VERSION ""

NS_ :

BS_:

BU_: VCU ACU

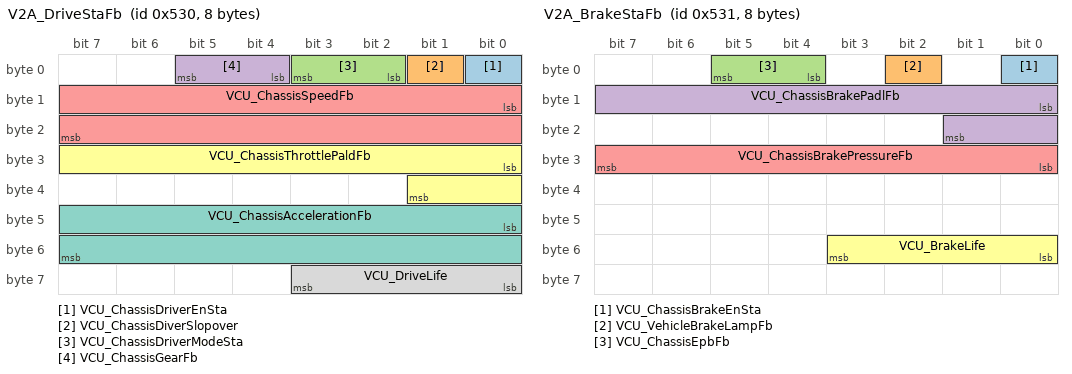
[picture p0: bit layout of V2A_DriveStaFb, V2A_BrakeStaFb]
BO_ 1328 V2A_DriveStaFb: 8 VCU
 SG_ VCU_ChassisDriverEnSta : 0|1@1+ (1,0) [0|1] ""   ACU
 SG_ VCU_ChassisDiverSlopover : 1|1@1+ (1,0) [0|1] ""   ACU
 SG_ VCU_ChassisDriverModeSta : 2|2@1+ (1,0) [0|3] ""   ACU
 SG_ VCU_ChassisGearFb : 4|2@1+ (1,0) [0|3] ""   ACU
 SG_ VCU_ChassisSpeedFb : 8|16@1- (0.01,0) [-50|50] "m/s"   ACU
 SG_ VCU_ChassisThrottlePaldFb : 24|10@1+ (0.1,0) [0|100] "%"   ACU
 SG_ VCU_ChassisAccelerationFb : 40|16@1- (0.01,0) [-20|20] "m/s2"   ACU
 SG_ VCU_DriveLife : 56|4@1+ (1,0) [0|15] ""   ACU

BO_ 1329 V2A_BrakeStaFb: 8 VCU
 SG_ VCU_ChassisBrakeEnSta : 0|1@1+ (1,0) [0|1] ""   ACU
 SG_ VCU_VehicleBrakeLampFb : 2|1@1+ (1,0) [0|1] ""   ACU
 SG_ VCU_ChassisEpbFb : 4|2@1+ (1,0) [0|3] ""   ACU
 SG_ VCU_ChassisBrakePadlFb : 8|10@1+ (0.1,0) [0|100] "%"   ACU
 SG_ VCU_ChassisBrakePressureFb : 24|8@1+ (1,0) [0|100] "bar"   ACU
 SG_ VCU_BrakeLife : 48|4@1+ (1,0) [0|15] ""   ACU

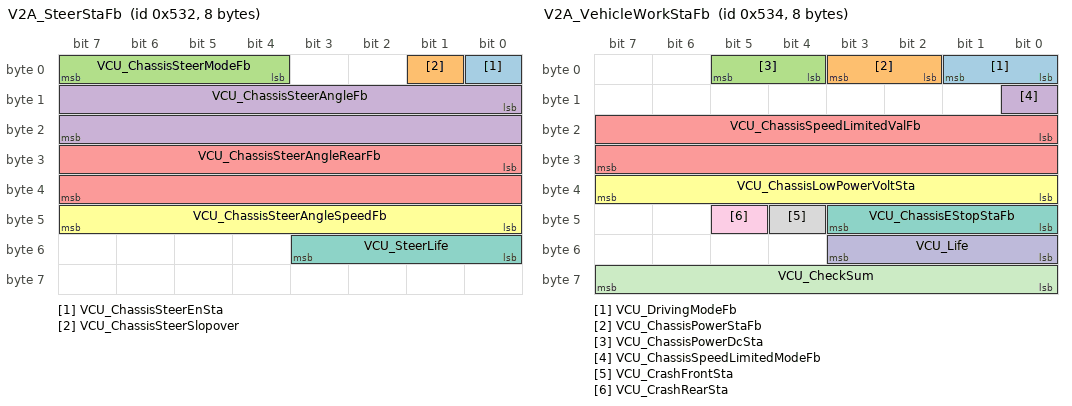
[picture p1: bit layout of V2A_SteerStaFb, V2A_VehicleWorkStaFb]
BO_ 1330 V2A_SteerStaFb: 8 VCU
 SG_ VCU_ChassisSteerEnSta : 0|1@1+ (1,0) [0|1] ""   ACU
 SG_ VCU_ChassisSteerSlopover : 1|1@1+ (1,0) [0|1] ""   ACU
 SG_ VCU_ChassisSteerModeFb : 4|4@1+ (1,0) [0|4] ""   ACU
 SG_ VCU_ChassisSteerAngleFb : 8|16@1- (1,0) [-500|500] "deg"   ACU
 SG_ VCU_ChassisSteerAngleRearFb : 24|16@1- (1,0) [-500|500] "deg"   ACU
 SG_ VCU_ChassisSteerAngleSpeedFb : 40|8@1+ (2,0) [0|500] "deg/s"   ACU
 SG_ VCU_SteerLife : 48|4@1+ (1,0) [0|15] ""   ACU

BO_ 1332 V2A_VehicleWorkStaFb: 8 VCU
 SG_ VCU_DrivingModeFb : 0|2@1+ (1,0) [0|3] ""   ACU
 SG_ VCU_ChassisPowerStaFb : 2|2@1+ (1,0) [0|3] ""   ACU
 SG_ VCU_ChassisPowerDcSta : 4|2@1+ (1,0) [0|2] ""   ACU
 SG_ VCU_ChassisSpeedLimitedModeFb : 8|1@1+ (1,0) [0|1] ""   ACU
 SG_ VCU_ChassisSpeedLimitedValFb : 16|16@1+ (0.1,0) [0|50] "m/s"   ACU
 SG_ VCU_ChassisLowPowerVoltSta : 32|8@1+ (0.1,0) [0|25] "V"   ACU
 SG_ VCU_ChassisEStopStaFb : 40|4@1+ (1,0) [0|3] ""   ACU
 SG_ VCU_CrashFrontSta : 44|1@1+ (1,0) [0|1] ""   ACU
 SG_ VCU_CrashRearSta : 45|1@1+ (1,0) [0|1] ""   ACU
 SG_ VCU_Life : 48|4@1+ (1,0) [0|15] ""   ACU
 SG_ VCU_CheckSum : 56|8@1+ (1,0) [0|255] ""   ACU

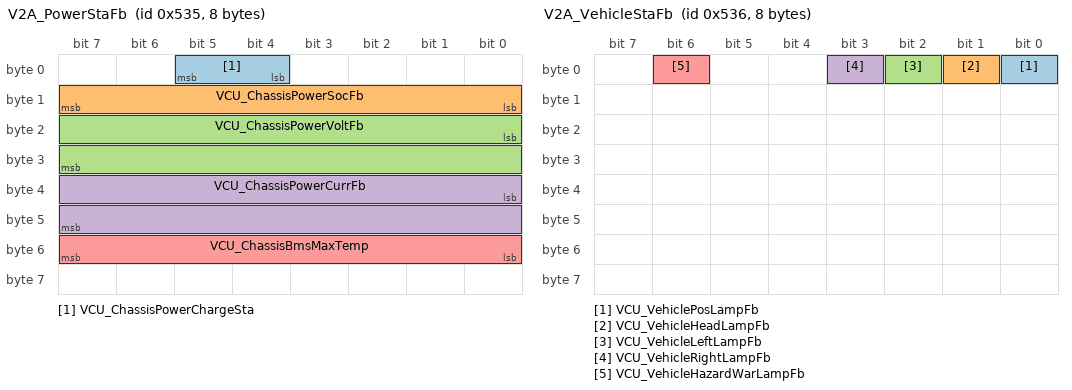
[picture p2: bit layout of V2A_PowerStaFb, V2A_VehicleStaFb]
BO_ 1333 V2A_PowerStaFb: 8 VCU
 SG_ VCU_ChassisPowerChargeSta : 4|2@1+ (1,0) [0|2] ""   ACU
 SG_ VCU_ChassisPowerSocFb : 8|8@1+ (1,0) [0|100] "%"   ACU
 SG_ VCU_ChassisPowerVoltFb : 16|16@1+ (0.1,0) [0|1000] "V"   ACU
 SG_ VCU_ChassisPowerCurrFb : 32|16@1+ (0.1,-1000) [-1000|1000] "A"   ACU
 SG_ VCU_ChassisBmsMaxTemp : 48|8@1+ (1,-40) [-40|80] "℃"   ACU

BO_ 1334 V2A_VehicleStaFb: 8 VCU
 SG_ VCU_VehiclePosLampFb : 0|1@1+ (1,0) [0|1] ""   ACU
 SG_ VCU_VehicleHeadLampFb : 1|1@1+ (1,0) [0|1] ""   ACU
 SG_ VCU_VehicleLeftLampFb : 2|1@1+ (1,0) [0|1] ""   ACU
 SG_ VCU_VehicleRightLampFb : 3|1@1+ (1,0) [0|1] ""   ACU
 SG_ VCU_VehicleHazardWarLampFb : 6|1@1+ (1,0) [0|1] ""   ACU

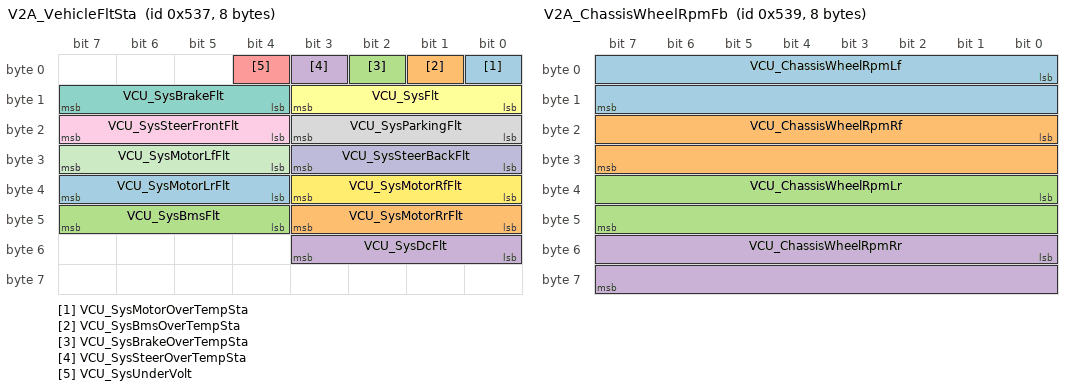
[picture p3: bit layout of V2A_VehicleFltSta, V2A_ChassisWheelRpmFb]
BO_ 1335 V2A_VehicleFltSta: 8 VCU
 SG_ VCU_SysMotorOverTempSta : 0|1@1+ (1,0) [0|1] ""   ACU
 SG_ VCU_SysBmsOverTempSta : 1|1@1+ (1,0) [0|1] ""   ACU
 SG_ VCU_SysBrakeOverTempSta : 2|1@1+ (1,0) [0|1] ""   ACU
 SG_ VCU_SysSteerOverTempSta : 3|1@1+ (1,0) [0|1] ""   ACU
 SG_ VCU_SysUnderVolt : 4|1@1+ (1,0) [0|1] ""   ACU
 SG_ VCU_SysFlt : 8|4@1+ (1,0) [0|4] ""   ACU
 SG_ VCU_SysBrakeFlt : 12|4@1+ (1,0) [0|4] ""   ACU
 SG_ VCU_SysParkingFlt : 16|4@1+ (1,0) [0|4] ""   ACU
 SG_ VCU_SysSteerFrontFlt : 20|4@1+ (1,0) [0|4] ""   ACU
 SG_ VCU_SysSteerBackFlt : 24|4@1+ (1,0) [0|4] ""   ACU
 SG_ VCU_SysMotorLfFlt : 28|4@1+ (1,0) [0|4] ""   ACU
 SG_ VCU_SysMotorRfFlt : 32|4@1+ (1,0) [0|4] ""   ACU
 SG_ VCU_SysMotorLrFlt : 36|4@1+ (1,0) [0|4] ""   ACU
 SG_ VCU_SysMotorRrFlt : 40|4@1+ (1,0) [0|4] ""   ACU
 SG_ VCU_SysBmsFlt : 44|4@1+ (1,0) [0|4] ""   ACU
 SG_ VCU_SysDcFlt : 48|4@1+ (1,0) [0|4] ""   ACU

BO_ 1337 V2A_ChassisWheelRpmFb: 8 VCU
 SG_ VCU_ChassisWheelRpmLf : 0|16@1- (1,0) [-2000|2000] "rpm"   ACU
 SG_ VCU_ChassisWheelRpmRf : 16|16@1- (1,0) [-2000|2000] "rpm"   ACU
 SG_ VCU_ChassisWheelRpmLr : 32|16@1- (1,0) [-2000|2000] "rpm"   ACU
 SG_ VCU_ChassisWheelRpmRr : 48|16@1- (1,0) [-2000|2000] "rpm"   ACU

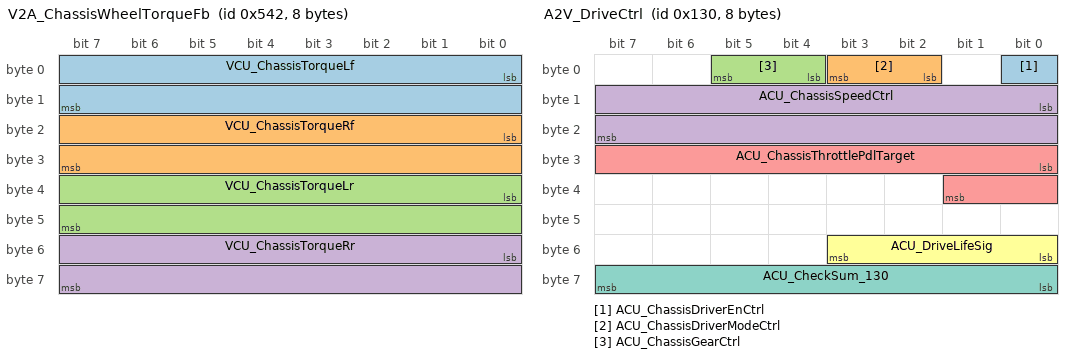
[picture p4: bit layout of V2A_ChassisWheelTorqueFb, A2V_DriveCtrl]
BO_ 1346 V2A_ChassisWheelTorqueFb: 8 VCU
 SG_ VCU_ChassisTorqueLf : 0|16@1- (0.1,0) [-200|200] "Nm"   ACU
 SG_ VCU_ChassisTorqueRf : 16|16@1- (0.1,0) [-200|200] "Nm"   ACU
 SG_ VCU_ChassisTorqueLr : 32|16@1- (0.1,0) [-200|200] "Nm"   ACU
 SG_ VCU_ChassisTorqueRr : 48|16@1- (0.1,0) [-200|200] "Nm"   ACU

BO_ 304 A2V_DriveCtrl: 8 ACU
 SG_ ACU_ChassisDriverEnCtrl : 0|1@1+ (1,0) [0|1] ""   VCU
 SG_ ACU_ChassisDriverModeCtrl : 2|2@1+ (1,0) [0|3] ""   VCU
 SG_ ACU_ChassisGearCtrl : 4|2@1+ (1,0) [0|3] ""   VCU
 SG_ ACU_ChassisSpeedCtrl : 8|16@1+ (0.01,0) [0|50] "m/s"   VCU
 SG_ ACU_ChassisThrottlePdlTarget : 24|10@1+ (0.1,0) [0|100] "%"   VCU
 SG_ ACU_DriveLifeSig : 48|4@1+ (1,0) [0|15] ""   VCU
 SG_ ACU_CheckSum_130 : 56|8@1+ (1,0) [0|255] ""   VCU

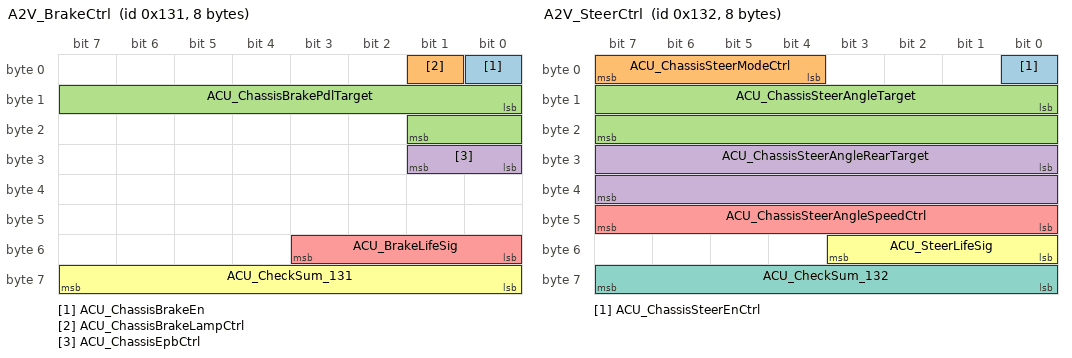
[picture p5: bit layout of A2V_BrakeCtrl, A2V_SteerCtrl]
BO_ 305 A2V_BrakeCtrl: 8 ACU
 SG_ ACU_ChassisBrakeEn : 0|1@1+ (1,0) [0|1] ""   VCU
 SG_ ACU_ChassisBrakeLampCtrl : 1|1@1+ (1,0) [0|1] ""   VCU
 SG_ ACU_ChassisBrakePdlTarget : 8|10@1+ (0.1,0) [0|100] "%"   VCU
 SG_ ACU_ChassisEpbCtrl : 24|2@1+ (1,0) [0|2] ""   VCU
 SG_ ACU_BrakeLifeSig : 48|4@1+ (1,0) [0|15] ""   VCU
 SG_ ACU_CheckSum_131 : 56|8@1+ (1,0) [0|255] ""   VCU

BO_ 306 A2V_SteerCtrl: 8 ACU
 SG_ ACU_ChassisSteerEnCtrl : 0|1@1+ (1,0) [0|1] ""   VCU
 SG_ ACU_ChassisSteerModeCtrl : 4|4@1+ (1,0) [0|4] ""   VCU
 SG_ ACU_ChassisSteerAngleTarget : 8|16@1- (1,0) [-500|500] "deg"   VCU
 SG_ ACU_ChassisSteerAngleRearTarget : 24|16@1- (1,0) [-500|500] "deg"   VCU
 SG_ ACU_ChassisSteerAngleSpeedCtrl : 40|8@1+ (2,0) [0|500] "deg/s"   VCU
 SG_ ACU_SteerLifeSig : 48|4@1+ (1,0) [0|15] ""   VCU
 SG_ ACU_CheckSum_132 : 56|8@1+ (1,0) [0|255] ""   VCU

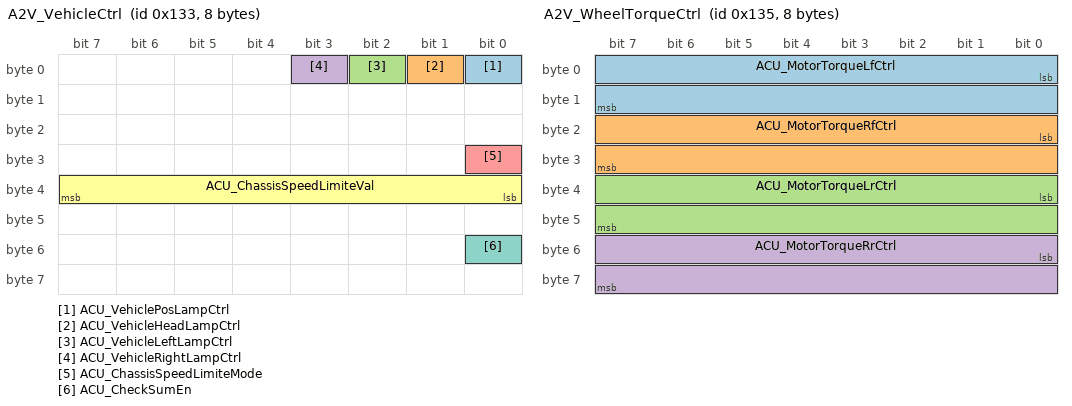
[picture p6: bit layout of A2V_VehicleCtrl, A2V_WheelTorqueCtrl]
BO_ 307 A2V_VehicleCtrl: 8 ACU
 SG_ ACU_VehiclePosLampCtrl : 0|1@1+ (1,0) [0|1] ""   VCU
 SG_ ACU_VehicleHeadLampCtrl : 1|1@1+ (1,0) [0|1] ""   VCU
 SG_ ACU_VehicleLeftLampCtrl : 2|1@1+ (1,0) [0|1] ""   VCU
 SG_ ACU_VehicleRightLampCtrl : 3|1@1+ (1,0) [0|1] ""   VCU
 SG_ ACU_ChassisSpeedLimiteMode : 24|1@1+ (1,0) [0|1] ""   VCU
 SG_ ACU_ChassisSpeedLimiteVal : 32|8@1+ (0.1,0) [1|20] "m/s"   VCU
 SG_ ACU_CheckSumEn : 48|1@1+ (1,0) [0|1] ""   VCU

BO_ 309 A2V_WheelTorqueCtrl: 8 ACU
 SG_ ACU_MotorTorqueLfCtrl : 0|16@1- (0.1,0) [-200|200] "Nm"   VCU
 SG_ ACU_MotorTorqueRfCtrl : 16|16@1- (0.1,0) [-200|200] "Nm"   VCU
 SG_ ACU_MotorTorqueLrCtrl : 32|16@1- (0.1,0) [-200|200] "Nm"   VCU
 SG_ ACU_MotorTorqueRrCtrl : 48|16@1- (0.1,0) [-200|200] "Nm"   VCU

CM_ BO_ 1328 "车辆驱动状态反馈";
CM_ SG_ 1328 VCU_ChassisDriverEnSta "驱动使能状态";
CM_ SG_ 1328 VCU_ChassisDiverSlopover "驱动控制越界提醒";
CM_ SG_ 1328 VCU_ChassisDriverModeSta "驱动模式反馈";
CM_ SG_ 1328 VCU_ChassisGearFb "档位状态";
CM_ SG_ 1328 VCU_ChassisSpeedFb "车速实际反馈";
CM_ SG_ 1328 VCU_ChassisThrottlePaldFb "油门请求值反馈";
CM_ SG_ 1328 VCU_ChassisAccelerationFb "车辆加速度";
CM_ SG_ 1328 VCU_DriveLife "VCU循环计数";
CM_ BO_ 1329 "车辆制动状态反馈";
CM_ SG_ 1329 VCU_ChassisBrakeEnSta "制动使能状态";
CM_ SG_ 1329 VCU_VehicleBrakeLampFb "制动灯状态反馈";
CM_ SG_ 1329 VCU_ChassisEpbFb "驻车状态";
CM_ SG_ 1329 VCU_ChassisBrakePadlFb "制动踏板值反馈";
CM_ SG_ 1329 VCU_ChassisBrakePressureFb "制动压力反馈";
CM_ SG_ 1329 VCU_BrakeLife "VCU循环计数";
CM_ BO_ 1330 "车辆转向状态反馈";
CM_ SG_ 1330 VCU_ChassisSteerEnSta "转向使能状态";
CM_ SG_ 1330 VCU_ChassisSteerSlopover "转向控制越界提醒";
CM_ SG_ 1330 VCU_ChassisSteerModeFb "转向模式反馈";
CM_ SG_ 1330 VCU_ChassisSteerAngleFb "前转向方向盘转角反馈";
CM_ SG_ 1330 VCU_ChassisSteerAngleRearFb "后转向方向盘转角反馈";
CM_ SG_ 1330 VCU_ChassisSteerAngleSpeedFb "设置的转向转角速度反馈";
CM_ SG_ 1330 VCU_SteerLife "VCU循环计数";
CM_ BO_ 1332 "车辆工作状态反馈";
CM_ SG_ 1332 VCU_DrivingModeFb "驾驶模式反馈";
CM_ SG_ 1332 VCU_ChassisPowerStaFb "车辆上电状态反馈";
CM_ SG_ 1332 VCU_ChassisPowerDcSta "DC工作状态";
CM_ SG_ 1332 VCU_ChassisSpeedLimitedModeFb "车辆限速状态";
CM_ SG_ 1332 VCU_ChassisSpeedLimitedValFb "车辆限速值反馈";
CM_ SG_ 1332 VCU_ChassisLowPowerVoltSta "低压蓄电池电压";
CM_ SG_ 1332 VCU_ChassisEStopStaFb "紧急停车状态反馈";
CM_ SG_ 1332 VCU_CrashFrontSta "车辆前碰撞传感器反馈";
CM_ SG_ 1332 VCU_CrashRearSta "车辆后碰撞传感器反馈";
CM_ SG_ 1332 VCU_Life "VCU循环计数";
CM_ SG_ 1332 VCU_CheckSum "校验sum=byte0 xor byte1 xor...byte6";
CM_ BO_ 1333 "车辆动力电源状态反馈";
CM_ SG_ 1333 VCU_ChassisPowerChargeSta "车辆充电状态";
CM_ SG_ 1333 VCU_ChassisPowerSocFb "车辆动力电池电量";
CM_ SG_ 1333 VCU_ChassisPowerVoltFb "车辆动力电池电压";
CM_ SG_ 1333 VCU_ChassisPowerCurrFb "车辆动力电池电流";
CM_ SG_ 1333 VCU_ChassisBmsMaxTemp "BMS最高单体温度";
CM_ BO_ 1334 "车辆车身及灯光反馈";
CM_ SG_ 1334 VCU_VehiclePosLampFb "位置灯状态反馈";
CM_ SG_ 1334 VCU_VehicleHeadLampFb "近光灯状态反馈";
CM_ SG_ 1334 VCU_VehicleLeftLampFb "左转向灯状态反馈";
CM_ SG_ 1334 VCU_VehicleRightLampFb "右转向灯状态反馈";
CM_ SG_ 1334 VCU_VehicleHazardWarLampFb "危险警示灯开关状态";
CM_ BO_ 1335 "车辆警告和故障";
CM_ SG_ 1335 VCU_SysMotorOverTempSta "电机系统过温";
CM_ SG_ 1335 VCU_SysBmsOverTempSta "电池系统过温";
CM_ SG_ 1335 VCU_SysBrakeOverTempSta "制动系统过温";
CM_ SG_ 1335 VCU_SysSteerOverTempSta "转向系统过温";
CM_ SG_ 1335 VCU_SysUnderVolt "蓄电池电压过低";
CM_ SG_ 1335 VCU_SysFlt "系统故障";
CM_ SG_ 1335 VCU_SysBrakeFlt "制动系统故障";
CM_ SG_ 1335 VCU_SysParkingFlt "驻车系统故障";
CM_ SG_ 1335 VCU_SysSteerFrontFlt "前转向系统故障";
CM_ SG_ 1335 VCU_SysSteerBackFlt "后转向系统故障";
CM_ SG_ 1335 VCU_SysMotorLfFlt "左前电机系统故障";
CM_ SG_ 1335 VCU_SysMotorRfFlt "右前电机系统故障";
CM_ SG_ 1335 VCU_SysMotorLrFlt "左后电机系统故障";
CM_ SG_ 1335 VCU_SysMotorRrFlt "右后电机系统故障";
CM_ SG_ 1335 VCU_SysBmsFlt "BMS系统故障";
CM_ SG_ 1335 VCU_SysDcFlt "DC系统故障";
CM_ BO_ 1337 "车轮转速反馈";
CM_ SG_ 1337 VCU_ChassisWheelRpmLf "左前轮转速";
CM_ SG_ 1337 VCU_ChassisWheelRpmRf "右前轮转速";
CM_ SG_ 1337 VCU_ChassisWheelRpmLr "左后轮转速";
CM_ SG_ 1337 VCU_ChassisWheelRpmRr "右后轮转速";
CM_ BO_ 1346 "车轮扭矩反馈";
CM_ SG_ 1346 VCU_ChassisTorqueLf "左前轮扭矩";
CM_ SG_ 1346 VCU_ChassisTorqueRf "右前轮扭矩";
CM_ SG_ 1346 VCU_ChassisTorqueLr "左后轮扭矩";
CM_ SG_ 1346 VCU_ChassisTorqueRr "右后轮扭矩";
CM_ BO_ 304 "驱动控制报文";
CM_ SG_ 304 ACU_ChassisDriverEnCtrl "车辆驱动控制使能";
CM_ SG_ 304 ACU_ChassisDriverModeCtrl "驱动模式控制";
CM_ SG_ 304 ACU_ChassisGearCtrl "档位控制";
CM_ SG_ 304 ACU_ChassisSpeedCtrl "车辆速度控制";
CM_ SG_ 304 ACU_ChassisThrottlePdlTarget "车辆油门控制";
CM_ SG_ 304 ACU_DriveLifeSig "循环计数0~15";
CM_ SG_ 304 ACU_CheckSum_130 "校验sum=byte0 xor byte1 xor...byte6";
CM_ BO_ 305 "制动控制报文";
CM_ SG_ 305 ACU_ChassisBrakeEn "车辆刹车控制使能";
CM_ SG_ 305 ACU_ChassisBrakeLampCtrl "车辆刹车灯控制";
CM_ SG_ 305 ACU_ChassisBrakePdlTarget "车辆刹车控制";
CM_ SG_ 305 ACU_ChassisEpbCtrl "驻车控制";
CM_ SG_ 305 ACU_BrakeLifeSig "循环计数0~15";
CM_ SG_ 305 ACU_CheckSum_131 "校验sum=byte0 xor byte1 xor...byte6";
CM_ BO_ 306 "转向控制报文";
CM_ SG_ 306 ACU_ChassisSteerEnCtrl "车辆转向控制使能";
CM_ SG_ 306 ACU_ChassisSteerModeCtrl "转向模式控制";
CM_ SG_ 306 ACU_ChassisSteerAngleTarget "车辆转向控制（前）";
CM_ SG_ 306 ACU_ChassisSteerAngleRearTarget "车辆转向控制（后）";
CM_ SG_ 306 ACU_ChassisSteerAngleSpeedCtrl "车辆方向盘转角速度控制";
CM_ SG_ 306 ACU_SteerLifeSig "循环计数0~15";
CM_ SG_ 306 ACU_CheckSum_132 "校验sum=byte0 xor byte1 xor...byte6";
CM_ BO_ 307 "车身控制1";
CM_ SG_ 307 ACU_VehiclePosLampCtrl "位置灯控制";
CM_ SG_ 307 ACU_VehicleHeadLampCtrl "近光灯控制";
CM_ SG_ 307 ACU_VehicleLeftLampCtrl "左转向灯控制";
CM_ SG_ 307 ACU_VehicleRightLampCtrl "右转向灯控制";
CM_ SG_ 307 ACU_ChassisSpeedLimiteMode "限速控制";
CM_ SG_ 307 ACU_ChassisSpeedLimiteVal "速度限制值";
CM_ SG_ 307 ACU_CheckSumEn "校验模式使能(预留)";
CM_ BO_ 309 "电机单独控制(预留)";
CM_ SG_ 309 ACU_MotorTorqueLfCtrl "左前电机扭矩";
CM_ SG_ 309 ACU_MotorTorqueRfCtrl "右前电机扭矩";
CM_ SG_ 309 ACU_MotorTorqueLrCtrl "左后电机扭矩";
CM_ SG_ 309 ACU_MotorTorqueRrCtrl "右后电机扭矩";

BA_DEF_ BO_ "GenMsgCycleTime" INT 0 65535;
BA_DEF_ BO_  "GenMsgSendType" ENUM  "Cyclic","Event","IfActive","CE","CA","NoMsgSendType";
BA_DEF_DEF_ "GenMsgCycleTime" 1000;
BA_DEF_DEF_  "GenMsgSendType" "Cyclic";
BA_ "GenMsgCycleTime" BO_ 1328 20;
BA_ "GenMsgCycleTime" BO_ 1329 20;
BA_ "GenMsgCycleTime" BO_ 1330 20;
BA_ "GenMsgCycleTime" BO_ 1332 200;
BA_ "GenMsgCycleTime" BO_ 1333 200;
BA_ "GenMsgCycleTime" BO_ 1334 200;
BA_ "GenMsgCycleTime" BO_ 1335 200;
BA_ "GenMsgCycleTime" BO_ 1337 20;
BA_ "GenMsgCycleTime" BO_ 1346 20;
BA_ "GenMsgCycleTime" BO_ 304 20;
BA_ "GenMsgCycleTime" BO_ 305 20;
BA_ "GenMsgCycleTime" BO_ 306 20;
BA_ "GenMsgCycleTime" BO_ 307 200;
BA_ "GenMsgCycleTime" BO_ 309 20;

VAL_ 1328 VCU_ChassisDriverEnSta 0 "disable" 1 "enable(自动驾驶使能驱动控制)";
VAL_ 1328 VCU_ChassisDiverSlopover 0 "normal" 1 "over slop(越界超5%为越界)";
VAL_ 1328 VCU_ChassisDriverModeSta 0 "speed ctrl mode" 1 "throttle ctrl mode" 2 "reserve" 3 "reserve";
VAL_ 1328 VCU_ChassisGearFb 0 "no use" 1 "D" 2 "N" 3 "R";
VAL_ 1329 VCU_ChassisBrakeEnSta 0 "disable" 1 "enable";
VAL_ 1329 VCU_VehicleBrakeLampFb 0 "off" 1 "on";
VAL_ 1329 VCU_ChassisEpbFb 0 "release" 1 "brake" 2 "releasing" 3 "braking";
VAL_ 1330 VCU_ChassisSteerEnSta 0 "disable" 1 "enable";
VAL_ 1330 VCU_ChassisSteerSlopover 0 "normal" 1 "over slop";
VAL_ 1330 VCU_ChassisSteerModeFb 0 "front ackerman" 1 "same front and back" 2 "front different back" 3 "back ackrman" 4 "front back";
VAL_ 1332 VCU_DrivingModeFb 0 "standby" 1 "self driving" 2 "remote" 3 "man";
VAL_ 1332 VCU_ChassisPowerStaFb 0 "init" 1 "on acc" 2 "ready" 3 "off";
VAL_ 1332 VCU_ChassisPowerDcSta 0 "off" 1 "on" 2 "standby";
VAL_ 1332 VCU_ChassisSpeedLimitedModeFb 0 "default" 1 "limit";
VAL_ 1332 VCU_ChassisEStopStaFb 0 "no" 1 "chassis estop" 2 "remote estop" 3 "chassis err estop";
VAL_ 1332 VCU_CrashFrontSta 0 "off" 1 "collide";
VAL_ 1332 VCU_CrashRearSta 0 "off" 1 "collide";
VAL_ 1333 VCU_ChassisPowerChargeSta 0 "no charge" 1 "charge" 2 "charge full";
VAL_ 1334 VCU_VehiclePosLampFb 0 "off" 1 "on";
VAL_ 1334 VCU_VehicleHeadLampFb 0 "off" 1 "on";
VAL_ 1334 VCU_VehicleLeftLampFb 0 "off" 1 "on";
VAL_ 1334 VCU_VehicleRightLampFb 0 "off" 1 "on";
VAL_ 1334 VCU_VehicleHazardWarLampFb 0 "off" 1 "on";
VAL_ 1335 VCU_SysMotorOverTempSta 0 "normal" 1 "over temp";
VAL_ 1335 VCU_SysBmsOverTempSta 0 "normal" 1 "over temp";
VAL_ 1335 VCU_SysBrakeOverTempSta 0 "normal" 1 "over temp";
VAL_ 1335 VCU_SysSteerOverTempSta 0 "normal" 1 "over temp";
VAL_ 1335 VCU_SysUnderVolt 0 "normal" 1 "under volt";
VAL_ 1335 VCU_SysFlt 0 "normal" 1 "fault level 1" 2 "fault level 2" 3 "fault level 3" 4 "fault level 4";
VAL_ 1335 VCU_SysBrakeFlt 0 "normal" 1 "fault level 1" 2 "fault level 2" 3 "fault level 3" 4 "fault level 4";
VAL_ 1335 VCU_SysParkingFlt 0 "normal" 1 "fault level 1" 2 "fault level 2" 3 "fault level 3" 4 "fault level 4";
VAL_ 1335 VCU_SysSteerFrontFlt 0 "normal" 1 "fault level 1" 2 "fault level 2" 3 "fault level 3" 4 "fault level 4";
VAL_ 1335 VCU_SysSteerBackFlt 0 "normal" 1 "fault level 1" 2 "fault level 2" 3 "fault level 3" 4 "fault level 4";
VAL_ 1335 VCU_SysMotorLfFlt 0 "normal" 1 "fault level 1" 2 "fault level 2" 3 "fault level 3" 4 "fault level 4";
VAL_ 1335 VCU_SysMotorRfFlt 0 "normal" 1 "fault level 1" 2 "fault level 2" 3 "fault level 3" 4 "fault level 4";
VAL_ 1335 VCU_SysMotorLrFlt 0 "normal" 1 "fault level 1" 2 "fault level 2" 3 "fault level 3" 4 "fault level 4";
VAL_ 1335 VCU_SysMotorRrFlt 0 "normal" 1 "fault level 1" 2 "fault level 2" 3 "fault level 3" 4 "fault level 4";
VAL_ 1335 VCU_SysBmsFlt 0 "normal" 1 "fault level 1" 2 "fault level 2" 3 "fault level 3" 4 "fault level 4";
VAL_ 1335 VCU_SysDcFlt 0 "normal" 1 "fault level 1" 2 "fault level 2" 3 "fault level 3" 4 "fault level 4";
VAL_ 304 ACU_ChassisDriverEnCtrl 0 "disable" 1 "enable";
VAL_ 304 ACU_ChassisDriverModeCtrl 0 "speed ctrl mode" 1 "throttle ctrl mode" 2 "reserve1" 3 "reserve2";
VAL_ 304 ACU_ChassisGearCtrl 0 "default N" 1 "D" 2 "N" 3 "R";
VAL_ 305 ACU_ChassisBrakeEn 0 "disable" 1 "enable";
VAL_ 305 ACU_ChassisBrakeLampCtrl 0 "off（与VCU控制制动灯是或的关系）" 1 "on";
VAL_ 305 ACU_ChassisEpbCtrl 0 "default" 1 "brake" 2 "release";
VAL_ 306 ACU_ChassisSteerEnCtrl 0 "disable" 1 "enable";
VAL_ 306 ACU_ChassisSteerModeCtrl 0 "front ackerman" 1 "same front and back" 2 "front different back" 3 "back ackrman" 4 "front back";
VAL_ 307 ACU_VehiclePosLampCtrl 0 "off" 1 "on";
VAL_ 307 ACU_VehicleHeadLampCtrl 0 "off" 1 "on";
VAL_ 307 ACU_VehicleLeftLampCtrl 0 "off" 1 "on";
VAL_ 307 ACU_VehicleRightLampCtrl 0 "off" 1 "on";
VAL_ 307 ACU_ChassisSpeedLimiteMode 0 "default" 1 "limit";
VAL_ 307 ACU_CheckSumEn 0 "enable" 1 "disable";
